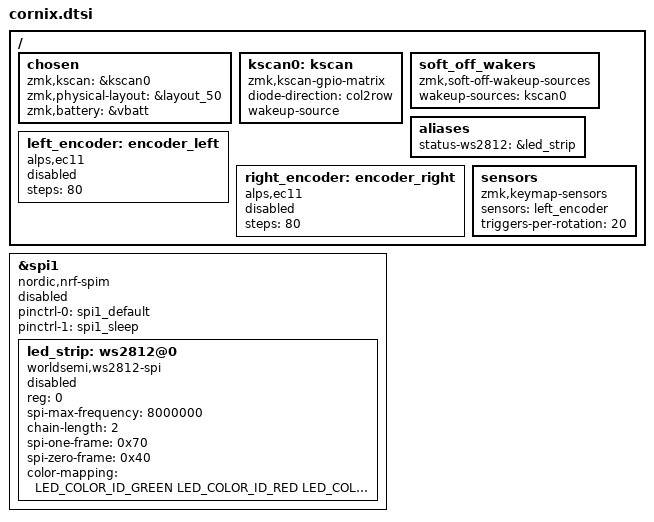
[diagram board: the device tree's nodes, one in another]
/*
 * Copyright (c) 2020 Pete Johanson
 *
 * SPDX-License-Identifier: MIT
 */

#include <dt-bindings/led/led.h>
#include "cornix-layouts.dtsi"

/ {
    chosen {
        zmk,kscan = &kscan0;
        zmk,physical-layout = &layout_50;
    };


    kscan0: kscan {
        compatible = "zmk,kscan-gpio-matrix";
        diode-direction = "col2row";
        wakeup-source;
    };

};

&spi1 {
    status = "disabled";

    compatible = "nordic,nrf-spim";


        pinctrl-0 = <&spi1_default>;
        pinctrl-1 = <&spi1_sleep>;
        pinctrl-names = "default", "sleep";

    led_strip: ws2812@0 {
        status = "disabled";
        compatible = "worldsemi,ws2812-spi";

        /* SPI */
        reg = <0>; /* ignored, but necessary for SPI bindings */
        spi-max-frequency = <8000000>;  // 8MHz

        /* WS2812 */
        chain-length = <2>; 
        spi-one-frame = <0x70>;
        spi-zero-frame = <0x40>;
        color-mapping = <LED_COLOR_ID_GREEN LED_COLOR_ID_RED LED_COLOR_ID_BLUE>;
    };
};

/ {
    soft_off_wakers {
        compatible = "zmk,soft-off-wakeup-sources";
        wakeup-sources = <&kscan0>;
    };

    aliases {
        status-ws2812 = &led_strip;
    };
    chosen {
        zmk,battery = &vbatt;
    };

    // Encoder definitions - hardware specific GPIO pins set in overlays
    left_encoder: encoder_left {
        compatible = "alps,ec11";
        steps = <80>; // Total pulses per complete rotation
        status = "disabled";
    };

    right_encoder: encoder_right {
        compatible = "alps,ec11";
        steps = <80>; // Total pulses per complete rotation
        status = "disabled";
    };

    // Sensor configuration for keymap integration
    sensors: sensors {
        compatible = "zmk,keymap-sensors";
        sensors = <&left_encoder>; // Default to left, overridden in right overlay
        triggers-per-rotation = <20>; // How many keymap events per rotation
    };
};
